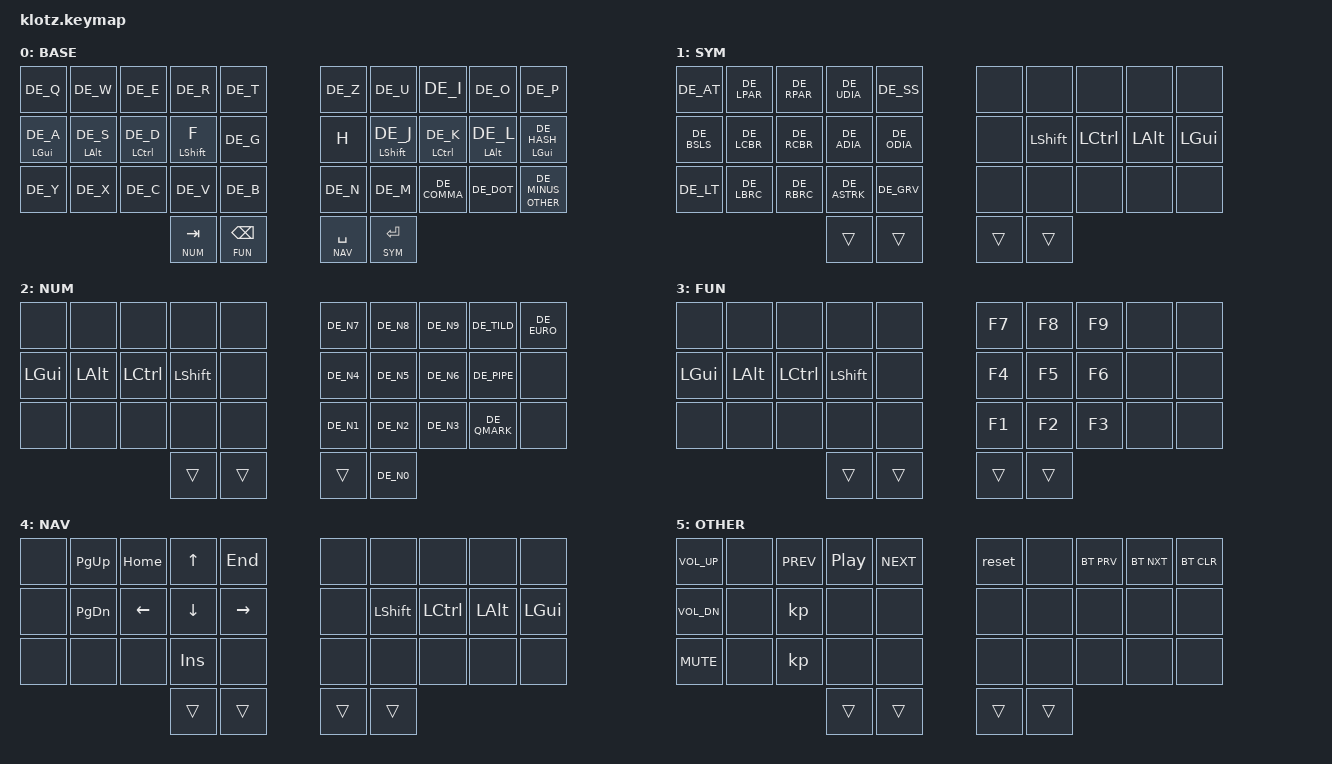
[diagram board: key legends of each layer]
#include <behaviors.dtsi>
#include <dt-bindings/zmk/keys.h>
#include <dt-bindings/zmk/bt.h>
#include <dt-bindings/zmk/outputs.h>
#include "keys_de.h"

#define BASE 0
#define SYM  1
#define NUM  2
#define FUN  3
#define NAV  4
#define OTHER 5

&mt {
  quick-tap-ms = <100>;
  global-quick-tap;
  flavor = "tap-preferred";
  tapping-term-ms = <170>;
};

/ {
    combos {
            compatible = "zmk,combos";
            combo_esc {
                timeout-ms = <50>;
                key-positions = <0 1>;
                bindings = <&kp ESC>;
            };
    };


        keymap {
                compatible = "zmk,keymap";

                base_layer {
                    label= "BASE";
                    bindings = <
    &kp DE_Q       &kp DE_W       &kp DE_E       &kp DE_R    &kp DE_T        &kp DE_Z       &kp DE_U       &kp DE_I       &kp DE_O       &kp DE_P
    &mt LGUI DE_A  &mt LALT DE_S  &mt LCTRL DE_D &mt LSHFT F &kp DE_G        &kp H          &mt LSHFT DE_J &mt LCTRL DE_K &mt LALT DE_L  &mt LGUI DE_HASH
    &kp DE_Y       &kp DE_X       &kp DE_C       &kp DE_V    &kp DE_B        &kp DE_N       &kp DE_M       &kp DE_COMMA   &kp DE_DOT     &lt OTHER DE_MINUS
                                                 &lt NUM TAB &lt FUN BSPC    &lt NAV SPACE  &lt SYM RET
                        >;
            sensor-bindings = <&inc_dec_kp C_VOL_UP C_VOL_DN>;
                };

                sym_layer {
                    label= "SYM";
                    bindings = <
    &kp DE_AT   &kp DE_LPAR &kp DE_RPAR  &kp DE_UDIA  &kp DE_SS       &none    &none     &none      &none    &none
    &kp DE_BSLS &kp DE_LCBR &kp DE_RCBR  &kp DE_ADIA  &kp DE_ODIA     &none    &kp LSHFT &kp LCTRL  &kp LALT &kp LGUI
    &kp DE_LT   &kp DE_LBRC &kp DE_RBRC  &kp DE_ASTRK &kp DE_GRV      &none    &none     &none      &none    &none
                                         &trans       &trans          &trans   &trans
                        >;
                    sensor-bindings = <&inc_dec_kp C_VOL_UP C_VOL_DN>;
            };

                num_layer {
                    label= "NUM";
                    bindings = <
    &none     &none    &none      &none     &none        &kp DE_N7 &kp DE_N8 &kp DE_N9 &kp DE_TILD   &kp DE_EURO
    &kp LGUI  &kp LALT &kp LCTRL  &kp LSHFT &none        &kp DE_N4 &kp DE_N5 &kp DE_N6 &kp DE_PIPE   &none
    &none     &none    &none      &none     &none        &kp DE_N1 &kp DE_N2 &kp DE_N3 &kp DE_QMARK  &none
                                  &trans    &trans       &trans    &kp DE_N0
                        >;
                    sensor-bindings = <&inc_dec_kp C_VOL_UP C_VOL_DN>;
            };

                fun_layer {
                    label= "FUN";
                    bindings = <
    &none     &none    &none      &none     &none        &kp F7   &kp F8  &kp F9  &none   &none
    &kp LGUI  &kp LALT &kp LCTRL  &kp LSHFT &none        &kp F4   &kp F5  &kp F6  &none   &none
    &none     &none    &none      &none     &none        &kp F1   &kp F2  &kp F3  &none   &none
                                  &trans    &trans       &trans   &trans
                        >;
                    sensor-bindings = <&inc_dec_kp C_VOL_UP C_VOL_DN>;
            };

                nav_layer {
                    label= "NAV";
                    bindings = <
    &none     &kp PG_UP &kp HOME   &kp UP   &kp END     &none    &none     &none     &none    &none
    &none     &kp PG_DN &kp LEFT   &kp DOWN &kp RIGHT   &none    &kp LSHFT &kp LCTRL &kp LALT &kp LGUI
    &none     &none     &none      &kp INS  &none        &none    &none     &none     &none    &none
                                   &trans  &trans       &trans   &trans
                        >;
                    sensor-bindings = <&inc_dec_kp C_VOL_UP C_VOL_DN>;
            };

                other_layer {
                    label= "OTHER";
                    bindings = <
    &kp C_VOL_UP &none &kp C_PREV  &kp C_PP        &kp C_NEXT         &reset   &none     &bt BT_PRV  &bt BT_NXT &bt BT_CLR
    &kp C_VOL_DN &none &kp         &none           &none              &none    &none     &none       &none      &none
    &kp C_MUTE   &none &kp         &none           &none              &none    &none     &none       &none      &none
                                   &trans          &trans             &trans   &trans
                        >;
                    sensor-bindings = <&inc_dec_kp C_VOL_UP C_VOL_DN>;
            };
        };
};
